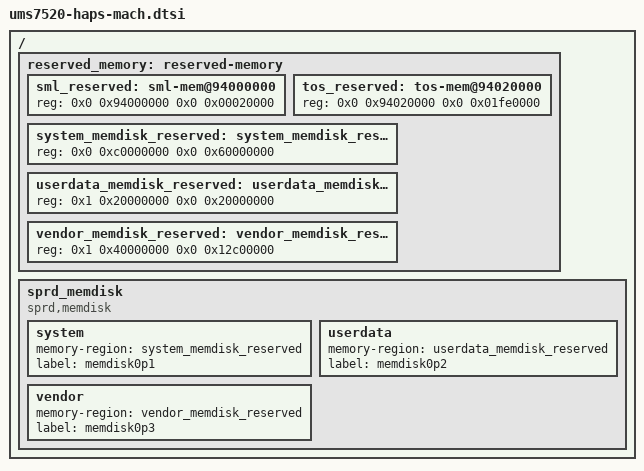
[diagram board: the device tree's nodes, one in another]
/*
 * Spreadtrum Qogirn6pro board common DTS file
 *
 * Copyright (C) 2019, Spreadtrum Communications Inc.
 *
 * This file is licensed under a dual GPLv2 or X11 license.
 */


/ {
	reserved_memory: reserved-memory {
		#address-cells = <2>;
		#size-cells = <2>;
		ranges;

		/* must be 64M aligned */
		sml_reserved: sml-mem@94000000 {
			reg = <0x0 0x94000000 0x0 0x00020000>;
		};

		tos_reserved: tos-mem@94020000 {
			reg = <0x0 0x94020000 0x0 0x01fe0000>;
		};

		system_memdisk_reserved: system_memdisk_reserved@c0000000{
			reg = <0x0 0xc0000000 0x0 0x60000000>;  /* system 1536M */
		};

		userdata_memdisk_reserved: userdata_memdisk_reserved@120000000{
			reg = <0x1 0x20000000 0x0 0x20000000>; /* userdata 512M */
		};

		vendor_memdisk_reserved: vendor_memdisk_reserved@140000000{
			reg = <0x1 0x40000000 0x0 0x12c00000>; /* vendor 300M */
		};
	};

	sprd_memdisk {
		compatible = "sprd,memdisk";

		system {
			memory-region = <&system_memdisk_reserved>;
			label = "memdisk0p1";
		};

		userdata {
			memory-region = <&userdata_memdisk_reserved>;
			label = "memdisk0p2";
		};

		vendor {
			memory-region = <&vendor_memdisk_reserved>;
			label = "memdisk0p3";
		};
	};
};
